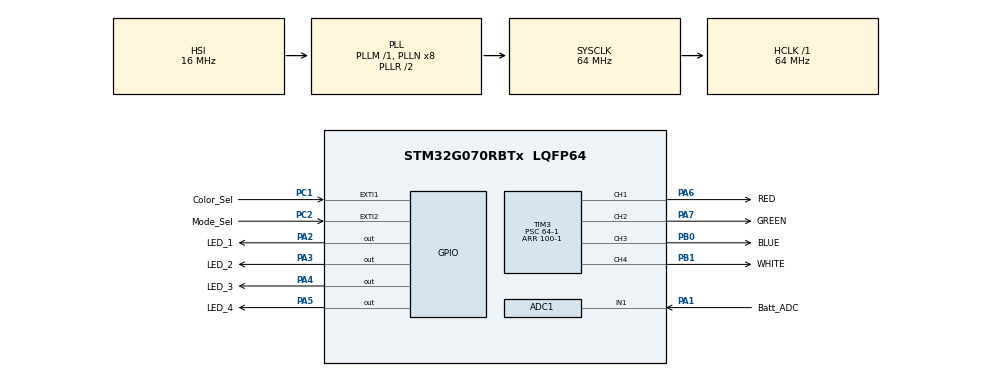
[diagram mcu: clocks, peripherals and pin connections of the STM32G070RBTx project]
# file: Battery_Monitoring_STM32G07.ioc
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ADC1.Channel-1\#ChannelRegularConversion=ADC_CHANNEL_1
ADC1.NbrOfConversionFlag=1
ADC1.Rank-1\#ChannelRegularConversion=1
ADC1.SamplingTime-1\#ChannelRegularConversion=ADC_SAMPLINGTIME_COMMON_1
ADC1.SelectedChannel=ADC_CHANNEL_1
ADC1.master=1
Dma.Request0=TIM3_CH1
Dma.Request1=TIM3_CH2
Dma.Request2=TIM3_CH3
Dma.Request3=TIM3_CH4
Dma.TIM3_CH1.0.Direction=DMA_MEMORY_TO_PERIPH
Dma.TIM3_CH1.0.EventEnable=DISABLE
Dma.TIM3_CH1.0.Instance=DMA1_Channel1
Dma.TIM3_CH1.0.MemDataAlignment=DMA_MDATAALIGN_HALFWORD
Dma.TIM3_CH1.0.MemInc=DMA_MINC_ENABLE
Dma.TIM3_CH1.0.Mode=DMA_NORMAL
Dma.TIM3_CH1.0.PeriphDataAlignment=DMA_PDATAALIGN_HALFWORD
Dma.TIM3_CH1.0.PeriphInc=DMA_PINC_DISABLE
Dma.TIM3_CH1.0.Polarity=HAL_DMAMUX_REQ_GEN_RISING
Dma.TIM3_CH1.0.Priority=DMA_PRIORITY_LOW
Dma.TIM3_CH1.0.RequestNumber=1
Dma.TIM3_CH1.0.SignalID=NONE
Dma.TIM3_CH1.0.SyncEnable=DISABLE
Dma.TIM3_CH1.0.SyncPolarity=HAL_DMAMUX_SYNC_NO_EVENT
Dma.TIM3_CH1.0.SyncRequestNumber=1
Dma.TIM3_CH1.0.SyncSignalID=NONE
Dma.TIM3_CH2.1.Direction=DMA_MEMORY_TO_PERIPH
Dma.TIM3_CH2.1.EventEnable=DISABLE
Dma.TIM3_CH2.1.Instance=DMA1_Channel2
Dma.TIM3_CH2.1.MemDataAlignment=DMA_MDATAALIGN_HALFWORD
Dma.TIM3_CH2.1.MemInc=DMA_MINC_ENABLE
Dma.TIM3_CH2.1.Mode=DMA_NORMAL
Dma.TIM3_CH2.1.PeriphDataAlignment=DMA_PDATAALIGN_HALFWORD
Dma.TIM3_CH2.1.PeriphInc=DMA_PINC_DISABLE
Dma.TIM3_CH2.1.Polarity=HAL_DMAMUX_REQ_GEN_RISING
Dma.TIM3_CH2.1.Priority=DMA_PRIORITY_LOW
Dma.TIM3_CH2.1.RequestNumber=1
Dma.TIM3_CH2.1.SignalID=NONE
Dma.TIM3_CH2.1.SyncEnable=DISABLE
Dma.TIM3_CH2.1.SyncPolarity=HAL_DMAMUX_SYNC_NO_EVENT
Dma.TIM3_CH2.1.SyncRequestNumber=1
Dma.TIM3_CH2.1.SyncSignalID=NONE
Dma.TIM3_CH3.2.Direction=DMA_MEMORY_TO_PERIPH
Dma.TIM3_CH3.2.EventEnable=DISABLE
Dma.TIM3_CH3.2.Instance=DMA1_Channel3
Dma.TIM3_CH3.2.MemDataAlignment=DMA_MDATAALIGN_HALFWORD
Dma.TIM3_CH3.2.MemInc=DMA_MINC_ENABLE
Dma.TIM3_CH3.2.Mode=DMA_NORMAL
Dma.TIM3_CH3.2.PeriphDataAlignment=DMA_PDATAALIGN_HALFWORD
Dma.TIM3_CH3.2.PeriphInc=DMA_PINC_DISABLE
Dma.TIM3_CH3.2.Polarity=HAL_DMAMUX_REQ_GEN_RISING
Dma.TIM3_CH3.2.Priority=DMA_PRIORITY_LOW
Dma.TIM3_CH3.2.RequestNumber=1
Dma.TIM3_CH3.2.SignalID=NONE
Dma.TIM3_CH3.2.SyncEnable=DISABLE
Dma.TIM3_CH3.2.SyncPolarity=HAL_DMAMUX_SYNC_NO_EVENT
Dma.TIM3_CH3.2.SyncRequestNumber=1
Dma.TIM3_CH3.2.SyncSignalID=NONE
Dma.TIM3_CH4.3.Direction=DMA_MEMORY_TO_PERIPH
Dma.TIM3_CH4.3.EventEnable=DISABLE
Dma.TIM3_CH4.3.Instance=DMA1_Channel4
Dma.TIM3_CH4.3.MemDataAlignment=DMA_MDATAALIGN_HALFWORD
Dma.TIM3_CH4.3.MemInc=DMA_MINC_ENABLE
Dma.TIM3_CH4.3.Mode=DMA_NORMAL
Dma.TIM3_CH4.3.PeriphDataAlignment=DMA_PDATAALIGN_HALFWORD
Dma.TIM3_CH4.3.PeriphInc=DMA_PINC_DISABLE
Dma.TIM3_CH4.3.Polarity=HAL_DMAMUX_REQ_GEN_RISING
Dma.TIM3_CH4.3.Priority=DMA_PRIORITY_LOW
Dma.TIM3_CH4.3.RequestNumber=1
Dma.TIM3_CH4.3.SignalID=NONE
Dma.TIM3_CH4.3.SyncEnable=DISABLE
Dma.TIM3_CH4.3.SyncPolarity=HAL_DMAMUX_SYNC_NO_EVENT
Dma.TIM3_CH4.3.SyncRequestNumber=1
Dma.TIM3_CH4.3.SyncSignalID=NONE
Mcu.Family=STM32G0
Mcu.Name=STM32G070RBTx
Mcu.Package=LQFP64
NVIC.ADC1_IRQn=true\:0\:0\:false\:false\:true\:true\:true\:true
NVIC.DMA1_Ch4_7_DMAMUX1_OVR_IRQn=true\:0\:0\:false\:false\:true\:false\:true\:true
NVIC.DMA1_Channel1_IRQn=true\:0\:0\:false\:false\:true\:false\:true\:true
NVIC.DMA1_Channel2_3_IRQn=true\:0\:0\:false\:false\:true\:false\:true\:true
NVIC.EXTI0_1_IRQn=true\:0\:0\:false\:false\:true\:true\:true\:true
NVIC.EXTI2_3_IRQn=true\:0\:0\:false\:false\:true\:true\:true\:true
PA1.GPIO_Label=Batt_ADC
PA1.Mode=IN1
PA1.Signal=ADC1_IN1
PA13.Mode=Serial_Wire
PA13.Signal=SYS_SWDIO
PA14-BOOT0.Mode=Serial_Wire
PA14-BOOT0.Signal=SYS_SWCLK
PA2.GPIO_Label=LED_1
PA2.Signal=GPIO_Output
PA3.GPIO_Label=LED_2
PA3.Signal=GPIO_Output
PA4.GPIO_Label=LED_3
PA4.Signal=GPIO_Output
PA5.GPIO_Label=LED_4
PA5.Signal=GPIO_Output
PA6.GPIO_Label=RED
PA6.Signal=S_TIM3_CH1
PA7.GPIO_Label=GREEN
PA7.Signal=S_TIM3_CH2
PB0.GPIO_Label=BLUE
PB0.Signal=S_TIM3_CH3
PB1.GPIO_Label=WHITE
PB1.Signal=S_TIM3_CH4
PC1.GPIO_Label=Color_Sel
PC1.Signal=GPXTI1
PC2.GPIO_Label=Mode_Sel
PC2.Signal=GPXTI2
ProjectManager.HeapSize=0x200
ProjectManager.StackSize=0x400
ProjectManager.TargetToolchain=Makefile
RCC.ADCFreq_Value=64000000
RCC.AHBFreq_Value=64000000
RCC.CortexFreq_Value=64000000
RCC.EXTERNAL_CLOCK_VALUE=48000
RCC.HCLKFreq_Value=64000000
RCC.HSE_VALUE=8000000
RCC.HSI_VALUE=16000000
RCC.LSE_VALUE=32768
RCC.SYSCLKFreq_VALUE=64000000
RCC.SYSCLKSource=RCC_SYSCLKSOURCE_PLLCLK
RCC.VCOOutputFreq_Value=128000000
SH.S_TIM3_CH1.0=TIM3_CH1,PWM Generation1 CH1
SH.S_TIM3_CH2.0=TIM3_CH2,PWM Generation2 CH2
SH.S_TIM3_CH3.0=TIM3_CH3,PWM Generation3 CH3
SH.S_TIM3_CH4.0=TIM3_CH4,PWM Generation4 CH4
TIM3.AutoReloadPreload=TIM_AUTORELOAD_PRELOAD_DISABLE
TIM3.Channel-PWM\ Generation1\ CH1=TIM_CHANNEL_1
TIM3.Channel-PWM\ Generation2\ CH2=TIM_CHANNEL_2
TIM3.Channel-PWM\ Generation3\ CH3=TIM_CHANNEL_3
TIM3.Channel-PWM\ Generation4\ CH4=TIM_CHANNEL_4
TIM3.Period=100-1
TIM3.Prescaler=64-1
VP_SYS_VS_DBSignals.Mode=DisableDeadBatterySignals
VP_TIM3_VS_ClockSourceINT.Mode=Internal
board=custom

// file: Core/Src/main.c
<<<<<<< HEAD
/* USER CODE BEGIN Header */
/**
  ******************************************************************************
  * @file           : main.c
  * @brief          : Main program body
  ******************************************************************************
  * @attention
  *
  * Copyright (c) 2023 STMicroelectronics.
  * All rights reserved.
  *
  * This software is licensed under terms that can be found in the LICENSE file
  * in the root directory of this software component.
  * If no LICENSE file comes with this software, it is provided AS-IS.
  *
  ******************************************************************************
  */
/* USER CODE END Header */
#include "main.h"
#include "adc.h"
#include "dma.h"
#include "tim.h"
#include "gpio.h"

void SystemClock_Config(void);

int main(void)
{

  /* MCU Configuration--------------------------------------------------------*/

  /* Reset of all peripherals, Initializes the Flash interface and the Systick. */
  HAL_Init();

  /* Configure the system clock */
  SystemClock_Config();

  /* Initialize all configured peripherals */
  MX_GPIO_Init();
  MX_DMA_Init();
  MX_TIM3_Init();
  MX_ADC1_Init();

  /* Infinite loop */
  while (1)
  {

  }
}

void SystemClock_Config(void)
{
  RCC_OscInitTypeDef RCC_OscInitStruct = {0};
  RCC_ClkInitTypeDef RCC_ClkInitStruct = {0};

  /** Configure the main internal regulator output voltage
  */
  HAL_PWREx_ControlVoltageScaling(PWR_REGULATOR_VOLTAGE_SCALE1);

  /** Initializes the RCC Oscillators according to the specified parameters
  * in the RCC_OscInitTypeDef structure.
  */
  RCC_OscInitStruct.OscillatorType = RCC_OSCILLATORTYPE_HSI;
  RCC_OscInitStruct.HSIState = RCC_HSI_ON;
  RCC_OscInitStruct.HSIDiv = RCC_HSI_DIV1;
  RCC_OscInitStruct.HSICalibrationValue = RCC_HSICALIBRATION_DEFAULT;
  RCC_OscInitStruct.PLL.PLLState = RCC_PLL_ON;
  RCC_OscInitStruct.PLL.PLLSource = RCC_PLLSOURCE_HSI;
  RCC_OscInitStruct.PLL.PLLM = RCC_PLLM_DIV1;
  RCC_OscInitStruct.PLL.PLLN = 8;
  RCC_OscInitStruct.PLL.PLLP = RCC_PLLP_DIV2;
  RCC_OscInitStruct.PLL.PLLR = RCC_PLLR_DIV2;
  if (HAL_RCC_OscConfig(&RCC_OscInitStruct) != HAL_OK)
  {
    Error_Handler();
  }

  /** Initializes the CPU, AHB and APB buses clocks
  */
  RCC_ClkInitStruct.ClockType = RCC_CLOCKTYPE_HCLK|RCC_CLOCKTYPE_SYSCLK
                              |RCC_CLOCKTYPE_PCLK1;
  RCC_ClkInitStruct.SYSCLKSource = RCC_SYSCLKSOURCE_PLLCLK;
  RCC_ClkInitStruct.AHBCLKDivider = RCC_SYSCLK_DIV1;
  RCC_ClkInitStruct.APB1CLKDivider = RCC_HCLK_DIV1;

  if (HAL_RCC_ClockConfig(&RCC_ClkInitStruct, FLASH_LATENCY_2) != HAL_OK)
  {
    Error_Handler();
  }
}

void Error_Handler(void)
{
  __disable_irq();
  while (1)
  {
  }
}

=======
/* USER CODE BEGIN Header */
/**
  ******************************************************************************
  * @file           : main.c
  * @brief          : Main program body
  ******************************************************************************
  * @attention
  *
  * Copyright (c) 2023 STMicroelectronics.
  * All rights reserved.
  *
  * This software is licensed under terms that can be found in the LICENSE file
  * in the root directory of this software component.
  * If no LICENSE file comes with this software, it is provided AS-IS.
  *
  ******************************************************************************
  */
/* USER CODE END Header */
#include "main.h"
#include "adc.h"
#include "dma.h"
#include "tim.h"
#include "gpio.h"
#include "Variables.h"

void SystemClock_Config(void);

int main(void)
{

  /* MCU Configuration--------------------------------------------------------*/

  /* Reset of all peripherals, Initializes the Flash interface and the Systick. */
  HAL_Init();

  /* Configure the system clock */
  SystemClock_Config();

  /* Initialize all configured peripherals */
  MX_GPIO_Init();
  MX_DMA_Init();
  MX_ADC1_Init();
  MX_TIM3_Init();
  /* USER CODE BEGIN 2 */
  TIM3->CCR1 = HIGH_Mode;
  TIM3->CCR2 = HIGH_Mode;
  TIM3->CCR3 = HIGH_Mode;
  TIM3->CCR4 = HIGH_Mode;
  /* USER CODE END 2 */

  /* Infinite loop */
  while (1)
  {

  }
}

void SystemClock_Config(void)
{
  RCC_OscInitTypeDef RCC_OscInitStruct = {0};
  RCC_ClkInitTypeDef RCC_ClkInitStruct = {0};

  /** Configure the main internal regulator output voltage
  */
  HAL_PWREx_ControlVoltageScaling(PWR_REGULATOR_VOLTAGE_SCALE1);

  /** Initializes the RCC Oscillators according to the specified parameters
  * in the RCC_OscInitTypeDef structure.
  */
  RCC_OscInitStruct.OscillatorType = RCC_OSCILLATORTYPE_HSI;
  RCC_OscInitStruct.HSIState = RCC_HSI_ON;
  RCC_OscInitStruct.HSIDiv = RCC_HSI_DIV1;
  RCC_OscInitStruct.HSICalibrationValue = RCC_HSICALIBRATION_DEFAULT;
  RCC_OscInitStruct.PLL.PLLState = RCC_PLL_ON;
  RCC_OscInitStruct.PLL.PLLSource = RCC_PLLSOURCE_HSI;
  RCC_OscInitStruct.PLL.PLLM = RCC_PLLM_DIV1;
  RCC_OscInitStruct.PLL.PLLN = 8;
  RCC_OscInitStruct.PLL.PLLP = RCC_PLLP_DIV2;
  RCC_OscInitStruct.PLL.PLLR = RCC_PLLR_DIV2;
  if (HAL_RCC_OscConfig(&RCC_OscInitStruct) != HAL_OK)
  {
    Error_Handler();
  }

  /** Initializes the CPU, AHB and APB buses clocks
  */
  RCC_ClkInitStruct.ClockType = RCC_CLOCKTYPE_HCLK|RCC_CLOCKTYPE_SYSCLK
                              |RCC_CLOCKTYPE_PCLK1;
  RCC_ClkInitStruct.SYSCLKSource = RCC_SYSCLKSOURCE_PLLCLK;
  RCC_ClkInitStruct.AHBCLKDivider = RCC_SYSCLK_DIV1;
  RCC_ClkInitStruct.APB1CLKDivider = RCC_HCLK_DIV1;

  if (HAL_RCC_ClockConfig(&RCC_ClkInitStruct, FLASH_LATENCY_2) != HAL_OK)
  {
    Error_Handler();
  }
}

void Error_Handler(void)
{
  __disable_irq();
  while (1)
  {
  }
}

>>>>>>> 3eca1d0bbe1aa4dfc8139960ad98441eb06ff2c8
